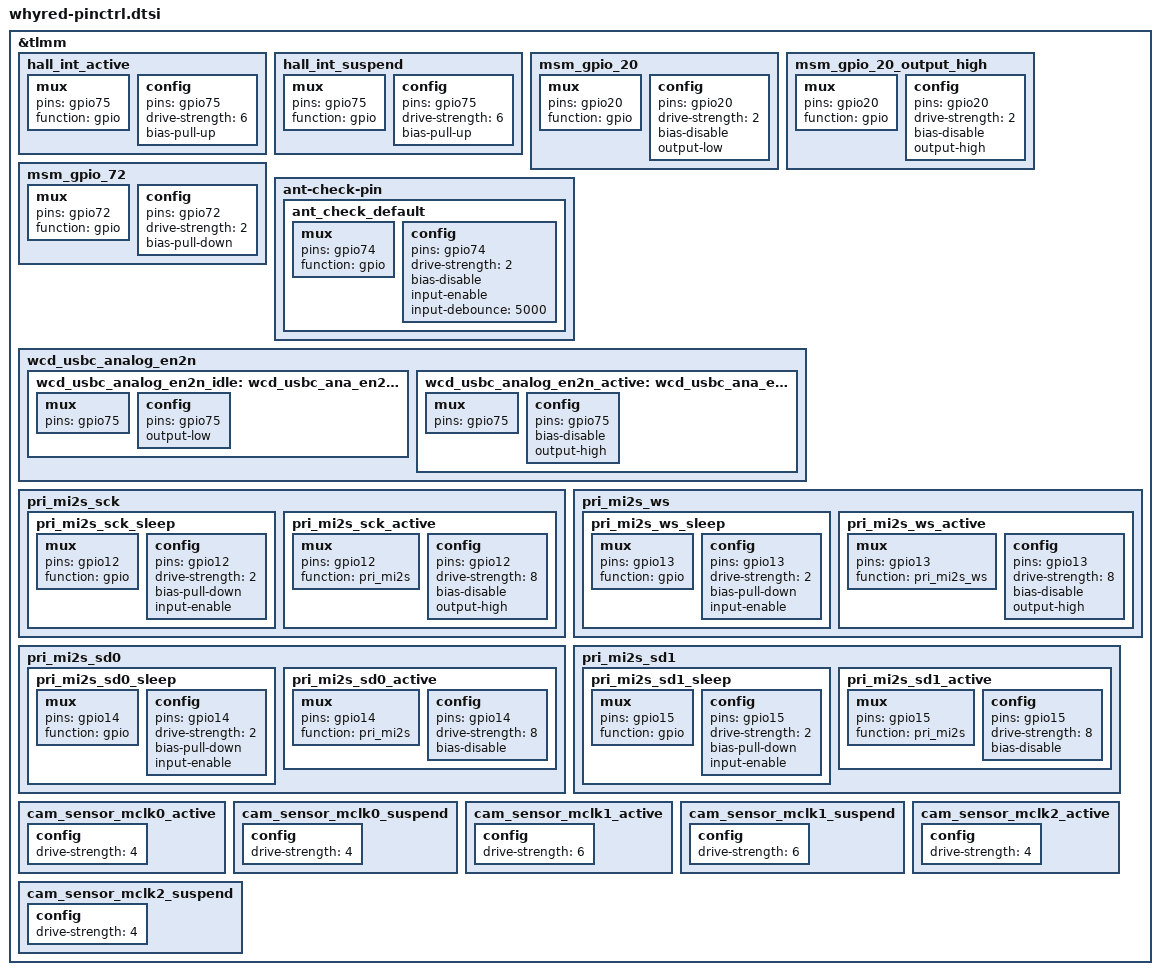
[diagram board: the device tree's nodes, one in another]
/* Copyright (c) 2017, The Linux Foundation. All rights reserved.
 * Copyright (C) 2019 XiaoMi, Inc.
 *
 * This program is free software; you can redistribute it and/or modify
 * it under the terms of the GNU General Public License version 2 and
 * only version 2 as published by the Free Software Foundation.
 *
 * This program is distributed in the hope that it will be useful,
 * but WITHOUT ANY WARRANTY; without even the implied warranty of
 * MERCHANTABILITY or FITNESS FOR A PARTICULAR PURPOSE.  See the
 * GNU General Public License for more details.
*/

&tlmm {
	hall_int_active: hall_int_active {
		mux {
			pins = "gpio75";
			function = "gpio";
		};

		config {
			pins = "gpio75";
			drive-strength = <6>;
			bias-pull-up;
		};
	};

	hall_int_suspend: hall_int_suspend {
		mux {
			pins = "gpio75";
			function = "gpio";
		};

		config {
			pins = "gpio75";
			drive-strength = <6>;
			bias-pull-up;
		};
	};

	msm_gpio_20: msm_gpio_20 {
		mux {
			pins="gpio20";
			function= "gpio";
		};

		config {
			pins= "gpio20";
			drive-strength = <2>;
			bias-disable;
			output-low;
		};
	};

	msm_gpio_20_output_high: msm_gpio_20_output_high {
		mux {
			pins = "gpio20";
			function = "gpio";
		};

		config {
			pins = "gpio20";
			drive-strength = <2>;
			bias-disable;
			output-high;
		};
	};

	msm_gpio_72: msm_gpio_72 {
		mux {
			pins = "gpio72";
			function = "gpio";
		};

		config {
			pins = "gpio72";
			drive-strength=<2>;
			bias-pull-down;
		};
	};

	ant-check-pin {
		ant_check_default: ant_check_default {
			mux {
				pins = "gpio74";
				function = "gpio";
			};

			config {
				pins = "gpio74";
				drive-strength = <2>;
				bias-disable;
				input-enable;
				input-debounce = <5000>;
			};
		};
	};

	wcd_usbc_analog_en2n {
		wcd_usbc_analog_en2n_idle: wcd_usbc_ana_en2n_idle {
			mux {
				pins = "gpio75";
			};

			config {
				pins = "gpio75";
				output-low;
				/delete-property/ output-high;
			};
		};

		wcd_usbc_analog_en2n_active: wcd_usbc_ana_en2n_active {
			mux {
				pins = "gpio75";
			};

			config {
				pins = "gpio75";
				bias-disable;
				output-high;
				/delete-property/ bias-pull-down;
				/delete-property/ output-low;
			};
		};
	};

	/* add pri_mi2s for smartpa */
	pri_mi2s_sck {
		pri_mi2s_sck_sleep: pri_mi2s_sck_sleep {
			mux {
				pins = "gpio12";
				function = "gpio";
			};

			config {
				pins = "gpio12";
				drive-strength = <2>;   /* 2 mA */
				bias-pull-down;         /* PULL DOWN */
				input-enable;
			};
		};

		pri_mi2s_sck_active: pri_mi2s_sck_active {
			mux {
				pins = "gpio12";
				function = "pri_mi2s";
			};

			config {
				pins = "gpio12";
				drive-strength = <8>;   /* 8 mA */
				bias-disable;           /* NO PULL */
				output-high;
			};
		};
	};

	pri_mi2s_ws {
		pri_mi2s_ws_sleep: pri_mi2s_ws_sleep {
			mux {
				pins = "gpio13";
				function = "gpio";
			};

			config {
				pins = "gpio13";
				drive-strength = <2>;   /* 2 mA */
				bias-pull-down;         /* PULL DOWN */
				input-enable;
			};
		};

		pri_mi2s_ws_active: pri_mi2s_ws_active {
			mux {
				pins = "gpio13";
				function = "pri_mi2s_ws";
			};

			config {
				pins = "gpio13";
				drive-strength = <8>;   /* 8 mA */
				bias-disable;           /* NO PULL */
				output-high;
			};
		};
	};

	pri_mi2s_sd0 {
		pri_mi2s_sd0_sleep: pri_mi2s_sd0_sleep {
			mux {
				pins = "gpio14";
				function = "gpio";
			};

			config {
				pins = "gpio14";
				drive-strength = <2>;   /* 2 mA */
				bias-pull-down;         /* PULL DOWN */
				input-enable;
			};
		};

		pri_mi2s_sd0_active: pri_mi2s_sd0_active {
			mux {
				pins = "gpio14";
				function = "pri_mi2s";
			};

			config {
				pins = "gpio14";
				drive-strength = <8>;   /* 8 mA */
				bias-disable;           /* NO PULL */
			};
		};
	};

	pri_mi2s_sd1 {
		pri_mi2s_sd1_sleep: pri_mi2s_sd1_sleep {
			mux {
				pins = "gpio15";
				function = "gpio";
			};

			config {
				pins = "gpio15";
				drive-strength = <2>;   /* 2 mA */
				bias-pull-down;         /* PULL DOWN */
				input-enable;
			};
		};

		pri_mi2s_sd1_active: pri_mi2s_sd1_active {
			mux {
				pins = "gpio15";
				function = "pri_mi2s";
			};

			config {
				pins = "gpio15";
				drive-strength = <8>;   /* 8 mA */
				bias-disable;           /* NO PULL */
			};
		};
	};

	cam_sensor_mclk0_active: cam_sensor_mclk0_active {
		/* MCLK0 */
		config {
			drive-strength = <4>; /* 2 MA */
		};
	};

	cam_sensor_mclk0_suspend: cam_sensor_mclk0_suspend {
		/* MCLK0 */
		config {
			drive-strength = <4>; /* 2 MA */
		};
	};

	cam_sensor_mclk1_active: cam_sensor_mclk1_active {
		/* MCLK1 */
		config {
			drive-strength = <6>; /* 2 MA */
		};
	};

	cam_sensor_mclk1_suspend: cam_sensor_mclk1_suspend {
		/* MCLK1 */
		config {
			drive-strength = <6>; /* 2 MA */
		};
	};

	cam_sensor_mclk2_active: cam_sensor_mclk2_active {
		/* MCLK1 */
		config {
			drive-strength = <4>; /* 2 MA */
		};
	};

	cam_sensor_mclk2_suspend: cam_sensor_mclk2_suspend {
		/* MCLK1 */
		config {
			drive-strength = <4>; /* 2 MA */
		};
	};
};
